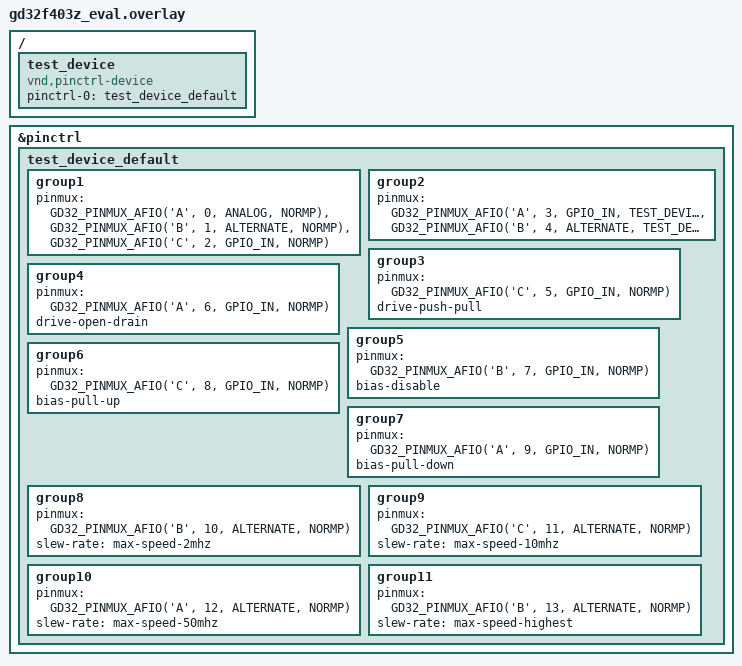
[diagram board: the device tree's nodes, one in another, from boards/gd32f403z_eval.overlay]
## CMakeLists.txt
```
# Copyright (c) 2021 Teslabs Engineering S.L.
# SPDX-License-Identifier: Apache-2.0

cmake_minimum_required(VERSION 3.28.0)
find_package(Zephyr REQUIRED HINTS $ENV{ZEPHYR_BASE})

project(pinctrl_gd32)

target_sources(app PRIVATE ../common/test_device.c)
if(CONFIG_PINCTRL_GD32_AF)
  target_sources(app PRIVATE src/main_af.c)
elseif(CONFIG_PINCTRL_GD32_AFIO)
  target_sources(app PRIVATE src/main_afio.c)
endif()
```

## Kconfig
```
# Copyright (c) 2021 Teslabs Engineering S.L.
# SPDX-License-Identifier: Apache-2.0

mainmenu "pinctrl GD32 DT Test"

source "Kconfig.zephyr"

config PINCTRL_TEST_NON_STATIC
	bool "Access to pin control configuration"
	select PINCTRL_NON_STATIC
	help
	  This option should be selected by unit tests that need to access the pin
	  control configuration defined in a device driver.
```

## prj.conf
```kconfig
# Copyright (c) 2021 Teslabs Engineering S.L.
# SPDX-License-Identifier: Apache-2.0

CONFIG_ZTEST=y
CONFIG_PINCTRL_TEST_NON_STATIC=y
```

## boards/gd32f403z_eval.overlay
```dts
/*
 * Copyright (c) 2021 Teslabs Engineering S.L.
 * SPDX-License-Identifier: Apache-2.0
 */

#define GD32_TEST_DEVICE_RMP GD32_REMAP(0, 0, 0x1U, 1)

/ {
	test_device: test_device {
		compatible = "vnd,pinctrl-device";
		pinctrl-0 = <&test_device_default>;
		pinctrl-names = "default";
	};
};

&pinctrl {
	test_device_default: test_device_default {
		/* Note: the groups are just meant for testing if properties and
		 * pins are parsed correctly, but do not necessarily represent a
		 * feasible combination
		 */
		group1 {
			pinmux = <GD32_PINMUX_AFIO('A', 0, ANALOG, NORMP)>,
				 <GD32_PINMUX_AFIO('B', 1, ALTERNATE, NORMP)>,
				 <GD32_PINMUX_AFIO('C', 2, GPIO_IN, NORMP)>;
		};

		group2 {
			pinmux = <GD32_PINMUX_AFIO('A', 3, GPIO_IN, TEST_DEVICE_RMP)>,
				 <GD32_PINMUX_AFIO('B', 4, ALTERNATE, TEST_DEVICE_RMP)>;
		};

		group3 {
			pinmux = <GD32_PINMUX_AFIO('C', 5, GPIO_IN, NORMP)>;
			drive-push-pull;
		};

		group4 {
			pinmux = <GD32_PINMUX_AFIO('A', 6, GPIO_IN, NORMP)>;
			drive-open-drain;
		};

		group5 {
			pinmux = <GD32_PINMUX_AFIO('B', 7, GPIO_IN, NORMP)>;
			bias-disable;
		};

		group6 {
			pinmux = <GD32_PINMUX_AFIO('C', 8, GPIO_IN, NORMP)>;
			bias-pull-up;
		};

		group7 {
			pinmux = <GD32_PINMUX_AFIO('A', 9, GPIO_IN, NORMP)>;
			bias-pull-down;
		};

		group8 {
			pinmux = <GD32_PINMUX_AFIO('B', 10, ALTERNATE, NORMP)>;
			slew-rate = "max-speed-2mhz";
		};

		group9 {
			pinmux = <GD32_PINMUX_AFIO('C', 11, ALTERNATE, NORMP)>;
			slew-rate = "max-speed-10mhz";
		};

		group10 {
			pinmux = <GD32_PINMUX_AFIO('A', 12, ALTERNATE, NORMP)>;
			slew-rate = "max-speed-50mhz";
		};

		group11 {
			pinmux = <GD32_PINMUX_AFIO('B', 13, ALTERNATE, NORMP)>;
			slew-rate = "max-speed-highest";
		};
	};
};
```

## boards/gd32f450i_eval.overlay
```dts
/*
 * Copyright (c) 2021 Teslabs Engineering S.L.
 * SPDX-License-Identifier: Apache-2.0
 */

/ {
	test_device: test_device {
		compatible = "vnd,pinctrl-device";
		pinctrl-0 = <&test_device_default>;
		pinctrl-names = "default";
	};
};

&pinctrl {
	test_device_default: test_device_default {
		/* Note: the groups are just meant for testing if properties and
		 * pins are parsed correctly, but do not necessarily represent a
		 * feasible combination
		 */
		group1 {
			pinmux = <GD32_PINMUX_AF('A', 0, AF0)>,
				 <GD32_PINMUX_AF('B', 1, AF1)>;
		};

		group2 {
			pinmux = <GD32_PINMUX_AF('C', 2, AF2)>;
			drive-push-pull;
		};

		group3 {
			pinmux = <GD32_PINMUX_AF('A', 3, AF3)>;
			drive-open-drain;
		};

		group4 {
			pinmux = <GD32_PINMUX_AF('B', 4, AF4)>;
			bias-disable;
		};

		group5 {
			pinmux = <GD32_PINMUX_AF('C', 5, AF5)>;
			bias-pull-up;
		};

		group6 {
			pinmux = <GD32_PINMUX_AF('A', 6, AF6)>;
			bias-pull-down;
		};

		group7 {
			pinmux = <GD32_PINMUX_AF('B', 7, AF7)>;
			slew-rate = "max-speed-2mhz";
		};

		group8 {
			pinmux = <GD32_PINMUX_AF('C', 8, AF8)>;
			slew-rate = "max-speed-25mhz";
		};

		group9 {
			pinmux = <GD32_PINMUX_AF('A', 9, AF9)>;
			slew-rate = "max-speed-50mhz";
		};

		group10 {
			pinmux = <GD32_PINMUX_AF('B', 10, AF10)>;
			slew-rate = "max-speed-200mhz";
		};

		group11 {
			pinmux = <GD32_PINMUX_AF('C', 11, ANALOG)>;
		};
	};
};
```

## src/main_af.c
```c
/*
 * Copyright (c) 2021 Teslabs Engineering S.L.
 * SPDX-License-Identifier: Apache-2.0
 */

#include <zephyr/drivers/pinctrl.h>
#include <zephyr/ztest.h>

/* pin configuration for test device */
#define TEST_DEVICE DT_NODELABEL(test_device)
PINCTRL_DT_DEV_CONFIG_DECLARE(TEST_DEVICE);
static const struct pinctrl_dev_config *pcfg = PINCTRL_DT_DEV_CONFIG_GET(TEST_DEVICE);

ZTEST(pinctrl_gd32, test_dt_extract)
{
	const struct pinctrl_state *scfg;
	pinctrl_soc_pin_t pin;

	zassert_equal(pcfg->state_cnt, 1U);

	scfg = &pcfg->states[0];

	zassert_equal(scfg->id, PINCTRL_STATE_DEFAULT);
	zassert_equal(scfg->pin_cnt, 12U);

	pin = scfg->pins[0];
	zassert_equal(GD32_PORT_GET(pin), 0);
	zassert_equal(GD32_PIN_GET(pin), 0);
	zassert_equal(GD32_AF_GET(pin), GD32_AF0);
	zassert_equal(GD32_PUPD_GET(pin), GD32_PUPD_NONE);
	zassert_equal(GD32_OTYPE_GET(pin), GD32_OTYPE_PP);
	zassert_equal(GD32_OSPEED_GET(pin), GD32_OSPEED_2MHZ);

	pin = scfg->pins[1];
	zassert_equal(GD32_PORT_GET(pin), 1);
	zassert_equal(GD32_PIN_GET(pin), 1);
	zassert_equal(GD32_AF_GET(pin), GD32_AF1);
	zassert_equal(GD32_PUPD_GET(pin), GD32_PUPD_NONE);
	zassert_equal(GD32_OTYPE_GET(pin), GD32_OTYPE_PP);
	zassert_equal(GD32_OSPEED_GET(pin), GD32_OSPEED_2MHZ);

	pin = scfg->pins[2];
	zassert_equal(GD32_PORT_GET(pin), 2);
	zassert_equal(GD32_PIN_GET(pin), 2);
	zassert_equal(GD32_AF_GET(pin), GD32_AF2);
	zassert_equal(GD32_PUPD_GET(pin), GD32_PUPD_NONE);
	zassert_equal(GD32_OTYPE_GET(pin), GD32_OTYPE_PP);
	zassert_equal(GD32_OSPEED_GET(pin), GD32_OSPEED_2MHZ);

	pin = scfg->pins[3];
	zassert_equal(GD32_PORT_GET(pin), 0);
	zassert_equal(GD32_PIN_GET(pin), 3);
	zassert_equal(GD32_AF_GET(pin), GD32_AF3);
	zassert_equal(GD32_PUPD_GET(pin), GD32_PUPD_NONE);
	zassert_equal(GD32_OTYPE_GET(pin), GD32_OTYPE_OD);
	zassert_equal(GD32_OSPEED_GET(pin), GD32_OSPEED_2MHZ);

	pin = scfg->pins[4];
	zassert_equal(GD32_PORT_GET(pin), 1);
	zassert_equal(GD32_PIN_GET(pin), 4);
	zassert_equal(GD32_AF_GET(pin), GD32_AF4);
	zassert_equal(GD32_PUPD_GET(pin), GD32_PUPD_NONE);
	zassert_equal(GD32_OTYPE_GET(pin), GD32_OTYPE_PP);
	zassert_equal(GD32_OSPEED_GET(pin), GD32_OSPEED_2MHZ);

	pin = scfg->pins[5];
	zassert_equal(GD32_PORT_GET(pin), 2);
	zassert_equal(GD32_PIN_GET(pin), 5);
	zassert_equal(GD32_AF_GET(pin), GD32_AF5);
	zassert_equal(GD32_PUPD_GET(pin), GD32_PUPD_PULLUP);
	zassert_equal(GD32_OTYPE_GET(pin), GD32_OTYPE_PP);
	zassert_equal(GD32_OSPEED_GET(pin), GD32_OSPEED_2MHZ);

	pin = scfg->pins[6];
	zassert_equal(GD32_PORT_GET(pin), 0);
	zassert_equal(GD32_PIN_GET(pin), 6);
	zassert_equal(GD32_AF_GET(pin), GD32_AF6);
	zassert_equal(GD32_PUPD_GET(pin), GD32_PUPD_PULLDOWN);
	zassert_equal(GD32_OTYPE_GET(pin), GD32_OTYPE_PP);
	zassert_equal(GD32_OSPEED_GET(pin), GD32_OSPEED_2MHZ);

	pin = scfg->pins[7];
	zassert_equal(GD32_PORT_GET(pin), 1);
	zassert_equal(GD32_PIN_GET(pin), 7);
	zassert_equal(GD32_AF_GET(pin), GD32_AF7);
	zassert_equal(GD32_PUPD_GET(pin), GD32_PUPD_NONE);
	zassert_equal(GD32_OTYPE_GET(pin), GD32_OTYPE_PP);
	zassert_equal(GD32_OSPEED_GET(pin), GD32_OSPEED_2MHZ);

	pin = scfg->pins[8];
	zassert_equal(GD32_PORT_GET(pin), 2);
	zassert_equal(GD32_PIN_GET(pin), 8);
	zassert_equal(GD32_AF_GET(pin), GD32_AF8);
	zassert_equal(GD32_PUPD_GET(pin), GD32_PUPD_NONE);
	zassert_equal(GD32_OTYPE_GET(pin), GD32_OTYPE_PP);
	zassert_equal(GD32_OSPEED_GET(pin), GD32_OSPEED_25MHZ);

	pin = scfg->pins[9];
	zassert_equal(GD32_PORT_GET(pin), 0);
	zassert_equal(GD32_PIN_GET(pin), 9);
	zassert_equal(GD32_AF_GET(pin), GD32_AF9);
	zassert_equal(GD32_PUPD_GET(pin), GD32_PUPD_NONE);
	zassert_equal(GD32_OTYPE_GET(pin), GD32_OTYPE_PP);
	zassert_equal(GD32_OSPEED_GET(pin), GD32_OSPEED_50MHZ);

	pin = scfg->pins[10];
	zassert_equal(GD32_PORT_GET(pin), 1);
	zassert_equal(GD32_PIN_GET(pin), 10);
	zassert_equal(GD32_AF_GET(pin), GD32_AF10);
	zassert_equal(GD32_PUPD_GET(pin), GD32_PUPD_NONE);
	zassert_equal(GD32_OTYPE_GET(pin), GD32_OTYPE_PP);
	zassert_equal(GD32_OSPEED_GET(pin), GD32_OSPEED_MAX);

	pin = scfg->pins[11];
	zassert_equal(GD32_PORT_GET(pin), 2);
	zassert_equal(GD32_PIN_GET(pin), 11);
	zassert_equal(GD32_AF_GET(pin), GD32_ANALOG);
	zassert_equal(GD32_PUPD_GET(pin), GD32_PUPD_NONE);
	zassert_equal(GD32_OTYPE_GET(pin), GD32_OTYPE_PP);
	zassert_equal(GD32_OSPEED_GET(pin), GD32_OSPEED_2MHZ);
}

ZTEST_SUITE(pinctrl_gd32, NULL, NULL, NULL, NULL, NULL);
```

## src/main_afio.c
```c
/*
 * Copyright (c) 2021 Teslabs Engineering S.L.
 * SPDX-License-Identifier: Apache-2.0
 */

#include <zephyr/drivers/pinctrl.h>
#include <zephyr/ztest.h>

/* pin configuration for test device */
#define TEST_DEVICE DT_NODELABEL(test_device)
PINCTRL_DT_DEV_CONFIG_DECLARE(TEST_DEVICE);
static const struct pinctrl_dev_config *pcfg = PINCTRL_DT_DEV_CONFIG_GET(TEST_DEVICE);

ZTEST(pinctrl_gd32, test_dt_extract)
{
	const struct pinctrl_state *scfg;
	pinctrl_soc_pin_t pin;

	zassert_equal(pcfg->state_cnt, 1U);

	scfg = &pcfg->states[0];

	zassert_equal(scfg->id, PINCTRL_STATE_DEFAULT);
	zassert_equal(scfg->pin_cnt, 14U);

	pin = scfg->pins[0];
	zassert_equal(GD32_PORT_GET(pin), 0);
	zassert_equal(GD32_PIN_GET(pin), 0);
	zassert_equal(GD32_MODE_GET(pin), GD32_MODE_ANALOG);
	zassert_equal(GD32_REMAP_GET(pin), GD32_NORMP);

	pin = scfg->pins[1];
	zassert_equal(GD32_PORT_GET(pin), 1);
	zassert_equal(GD32_PIN_GET(pin), 1);
	zassert_equal(GD32_MODE_GET(pin), GD32_MODE_ALTERNATE);
	zassert_equal(GD32_REMAP_GET(pin), GD32_NORMP);
	zassert_equal(GD32_OSPEED_GET(pin), GD32_OSPEED_2MHZ);

	pin = scfg->pins[2];
	zassert_equal(GD32_PORT_GET(pin), 2);
	zassert_equal(GD32_PIN_GET(pin), 2);
	zassert_equal(GD32_MODE_GET(pin), GD32_MODE_GPIO_IN);
	zassert_equal(GD32_REMAP_GET(pin), GD32_NORMP);
	zassert_equal(GD32_PUPD_GET(pin), GD32_PUPD_NONE);
	zassert_equal(GD32_OTYPE_GET(pin), GD32_OTYPE_PP);

	pin = scfg->pins[3];
	zassert_equal(GD32_PORT_GET(pin), 0);
	zassert_equal(GD32_PIN_GET(pin), 3);
	zassert_equal(GD32_MODE_GET(pin), GD32_MODE_GPIO_IN);
	zassert_equal(GD32_REMAP_REG_GET(GD32_REMAP_GET(pin)), 0);
	zassert_equal(GD32_REMAP_POS_GET(GD32_REMAP_GET(pin)), 0);
	zassert_equal(GD32_REMAP_MSK_GET(GD32_REMAP_GET(pin)), 0x1);
	zassert_equal(GD32_REMAP_VAL_GET(GD32_REMAP_GET(pin)), 1);
	zassert_equal(GD32_PUPD_GET(pin), GD32_PUPD_NONE);
	zassert_equal(GD32_OTYPE_GET(pin), GD32_OTYPE_PP);

	pin = scfg->pins[4];
	zassert_equal(GD32_PORT_GET(pin), 1);
	zassert_equal(GD32_PIN_GET(pin), 4);
	zassert_equal(GD32_MODE_GET(pin), GD32_MODE_ALTERNATE);
	zassert_equal(GD32_REMAP_REG_GET(GD32_REMAP_GET(pin)), 0);
	zassert_equal(GD32_REMAP_POS_GET(GD32_REMAP_GET(pin)), 0);
	zassert_equal(GD32_REMAP_MSK_GET(GD32_REMAP_GET(pin)), 0x1);
	zassert_equal(GD32_REMAP_VAL_GET(GD32_REMAP_GET(pin)), 1);
	zassert_equal(GD32_OSPEED_GET(pin), GD32_OSPEED_2MHZ);

	pin = scfg->pins[5];
	zassert_equal(GD32_PORT_GET(pin), 2);
	zassert_equal(GD32_PIN_GET(pin), 5);
	zassert_equal(GD32_MODE_GET(pin), GD32_MODE_GPIO_IN);
	zassert_equal(GD32_REMAP_GET(pin), GD32_NORMP);
	zassert_equal(GD32_PUPD_GET(pin), GD32_PUPD_NONE);
	zassert_equal(GD32_OTYPE_GET(pin), GD32_OTYPE_PP);

	pin = scfg->pins[6];
	zassert_equal(GD32_PORT_GET(pin), 0);
	zassert_equal(GD32_PIN_GET(pin), 6);
	zassert_equal(GD32_MODE_GET(pin), GD32_MODE_GPIO_IN);
	zassert_equal(GD32_REMAP_GET(pin), GD32_NORMP);
	zassert_equal(GD32_PUPD_GET(pin), GD32_PUPD_NONE);
	zassert_equal(GD32_OTYPE_GET(pin), GD32_OTYPE_OD);

	pin = scfg->pins[7];
	zassert_equal(GD32_PORT_GET(pin), 1);
	zassert_equal(GD32_PIN_GET(pin), 7);
	zassert_equal(GD32_MODE_GET(pin), GD32_MODE_GPIO_IN);
	zassert_equal(GD32_REMAP_GET(pin), GD32_NORMP);
	zassert_equal(GD32_PUPD_GET(pin), GD32_PUPD_NONE);
	zassert_equal(GD32_OTYPE_GET(pin), GD32_OTYPE_PP);

	pin = scfg->pins[8];
	zassert_equal(GD32_PORT_GET(pin), 2);
	zassert_equal(GD32_PIN_GET(pin), 8);
	zassert_equal(GD32_MODE_GET(pin), GD32_MODE_GPIO_IN);
	zassert_equal(GD32_REMAP_GET(pin), GD32_NORMP);
	zassert_equal(GD32_PUPD_GET(pin), GD32_PUPD_PULLUP);
	zassert_equal(GD32_OTYPE_GET(pin), GD32_OTYPE_PP);

	pin = scfg->pins[9];
	zassert_equal(GD32_PORT_GET(pin), 0);
	zassert_equal(GD32_PIN_GET(pin), 9);
	zassert_equal(GD32_MODE_GET(pin), GD32_MODE_GPIO_IN);
	zassert_equal(GD32_REMAP_GET(pin), GD32_NORMP);
	zassert_equal(GD32_PUPD_GET(pin), GD32_PUPD_PULLDOWN);
	zassert_equal(GD32_OTYPE_GET(pin), GD32_OTYPE_PP);

	pin = scfg->pins[10];
	zassert_equal(GD32_PORT_GET(pin), 1);
	zassert_equal(GD32_PIN_GET(pin), 10);
	zassert_equal(GD32_MODE_GET(pin), GD32_MODE_ALTERNATE);
	zassert_equal(GD32_REMAP_GET(pin), GD32_NORMP);
	zassert_equal(GD32_OSPEED_GET(pin), GD32_OSPEED_2MHZ);

	pin = scfg->pins[11];
	zassert_equal(GD32_PORT_GET(pin), 2);
	zassert_equal(GD32_PIN_GET(pin), 11);
	zassert_equal(GD32_MODE_GET(pin), GD32_MODE_ALTERNATE);
	zassert_equal(GD32_REMAP_GET(pin), GD32_NORMP);
	zassert_equal(GD32_OSPEED_GET(pin), GD32_OSPEED_10MHZ);

	pin = scfg->pins[12];
	zassert_equal(GD32_PORT_GET(pin), 0);
	zassert_equal(GD32_PIN_GET(pin), 12);
	zassert_equal(GD32_MODE_GET(pin), GD32_MODE_ALTERNATE);
	zassert_equal(GD32_REMAP_GET(pin), GD32_NORMP);
	zassert_equal(GD32_OSPEED_GET(pin), GD32_OSPEED_50MHZ);

	pin = scfg->pins[13];
	zassert_equal(GD32_PORT_GET(pin), 1);
	zassert_equal(GD32_PIN_GET(pin), 13);
	zassert_equal(GD32_MODE_GET(pin), GD32_MODE_ALTERNATE);
	zassert_equal(GD32_REMAP_GET(pin), GD32_NORMP);
	zassert_equal(GD32_OSPEED_GET(pin), GD32_OSPEED_MAX);
}

ZTEST_SUITE(pinctrl_gd32, NULL, NULL, NULL, NULL, NULL);
```
